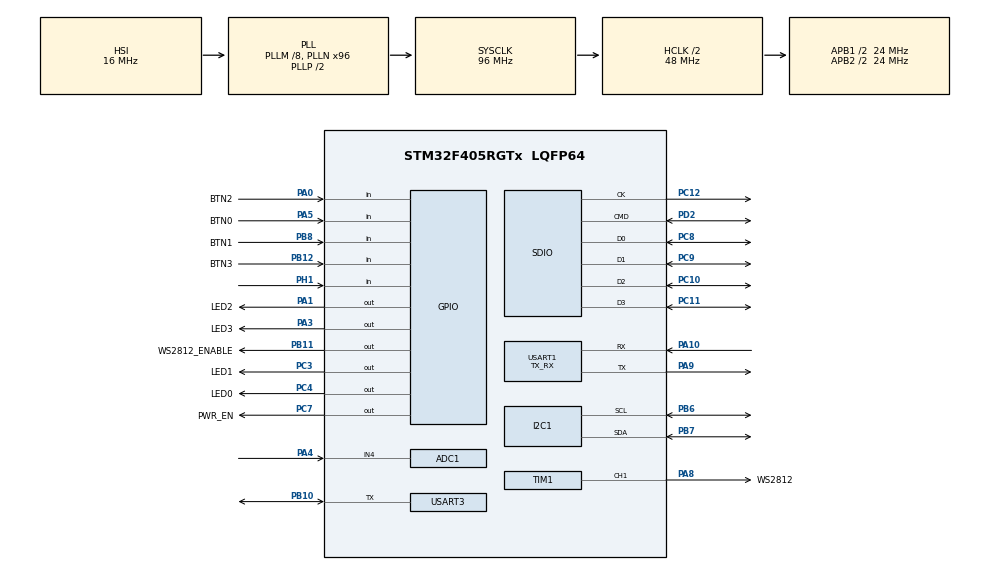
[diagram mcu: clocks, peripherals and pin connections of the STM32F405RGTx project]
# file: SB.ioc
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ADC1.Channel-0\#ChannelRegularConversion=ADC_CHANNEL_4
ADC1.Channel-3\#ChannelRegularConversion=ADC_CHANNEL_TEMPSENSOR
ADC1.DMAContinuousRequests=ENABLE
ADC1.EOCSelection=ADC_EOC_SEQ_CONV
ADC1.ExternalTrigConv=ADC_EXTERNALTRIGCONV_T3_TRGO
ADC1.InjNumberOfConversion=0
ADC1.NbrOfConversion=2
ADC1.NbrOfConversionFlag=1
ADC1.Rank-0\#ChannelRegularConversion=1
ADC1.Rank-3\#ChannelRegularConversion=2
ADC1.SamplingTime-0\#ChannelRegularConversion=ADC_SAMPLETIME_56CYCLES
ADC1.SamplingTime-3\#ChannelRegularConversion=ADC_SAMPLETIME_56CYCLES
ADC1.master=1
Dma.ADC1.0.Direction=DMA_PERIPH_TO_MEMORY
Dma.ADC1.0.FIFOMode=DMA_FIFOMODE_DISABLE
Dma.ADC1.0.Instance=DMA2_Stream0
Dma.ADC1.0.MemDataAlignment=DMA_MDATAALIGN_HALFWORD
Dma.ADC1.0.MemInc=DMA_MINC_ENABLE
Dma.ADC1.0.Mode=DMA_CIRCULAR
Dma.ADC1.0.PeriphDataAlignment=DMA_PDATAALIGN_HALFWORD
Dma.ADC1.0.PeriphInc=DMA_PINC_DISABLE
Dma.ADC1.0.Priority=DMA_PRIORITY_LOW
Dma.Request0=ADC1
Dma.Request1=TIM1_CH1
Dma.Request2=SDIO_RX
Dma.Request3=SDIO_TX
Dma.SDIO_RX.2.Direction=DMA_PERIPH_TO_MEMORY
Dma.SDIO_RX.2.FIFOMode=DMA_FIFOMODE_ENABLE
Dma.SDIO_RX.2.FIFOThreshold=DMA_FIFO_THRESHOLD_FULL
Dma.SDIO_RX.2.Instance=DMA2_Stream3
Dma.SDIO_RX.2.MemBurst=DMA_MBURST_INC4
Dma.SDIO_RX.2.MemDataAlignment=DMA_MDATAALIGN_WORD
Dma.SDIO_RX.2.MemInc=DMA_MINC_ENABLE
Dma.SDIO_RX.2.Mode=DMA_PFCTRL
Dma.SDIO_RX.2.PeriphBurst=DMA_PBURST_INC4
Dma.SDIO_RX.2.PeriphDataAlignment=DMA_PDATAALIGN_WORD
Dma.SDIO_RX.2.PeriphInc=DMA_PINC_DISABLE
Dma.SDIO_RX.2.Priority=DMA_PRIORITY_LOW
Dma.SDIO_TX.3.Direction=DMA_MEMORY_TO_PERIPH
Dma.SDIO_TX.3.FIFOMode=DMA_FIFOMODE_ENABLE
Dma.SDIO_TX.3.FIFOThreshold=DMA_FIFO_THRESHOLD_FULL
Dma.SDIO_TX.3.Instance=DMA2_Stream6
Dma.SDIO_TX.3.MemBurst=DMA_MBURST_INC4
Dma.SDIO_TX.3.MemDataAlignment=DMA_MDATAALIGN_WORD
Dma.SDIO_TX.3.MemInc=DMA_MINC_ENABLE
Dma.SDIO_TX.3.Mode=DMA_PFCTRL
Dma.SDIO_TX.3.PeriphBurst=DMA_PBURST_INC4
Dma.SDIO_TX.3.PeriphDataAlignment=DMA_PDATAALIGN_WORD
Dma.SDIO_TX.3.PeriphInc=DMA_PINC_DISABLE
Dma.SDIO_TX.3.Priority=DMA_PRIORITY_LOW
Dma.TIM1_CH1.1.Direction=DMA_MEMORY_TO_PERIPH
Dma.TIM1_CH1.1.FIFOMode=DMA_FIFOMODE_DISABLE
Dma.TIM1_CH1.1.Instance=DMA2_Stream1
Dma.TIM1_CH1.1.MemDataAlignment=DMA_MDATAALIGN_HALFWORD
Dma.TIM1_CH1.1.MemInc=DMA_MINC_ENABLE
Dma.TIM1_CH1.1.Mode=DMA_NORMAL
Dma.TIM1_CH1.1.PeriphDataAlignment=DMA_PDATAALIGN_HALFWORD
Dma.TIM1_CH1.1.PeriphInc=DMA_PINC_DISABLE
Dma.TIM1_CH1.1.Priority=DMA_PRIORITY_LOW
FATFS.BSP.number=1
FATFS.USE_DMA_CODE_SD=1
FATFS._MAX_SS=4096
FATFS._USE_LFN=1
FATFS0.BSP.STBoard=false
FATFS0.BSP.api=Unknown
FATFS0.BSP.instance=PH1-OSC_OUT
FATFS0.BSP.ip=GPIO
FATFS0.BSP.mode=Input
FATFS0.BSP.name=Detect_SDIO
FATFS0.BSP.solution=PH1-OSC_OUT
IWDG.Prescaler=IWDG_PRESCALER_32
IWDG.Reload=1000
Mcu.Family=STM32F4
Mcu.Name=STM32F405RGTx
Mcu.Package=LQFP64
NVIC.DMA2_Stream0_IRQn=true\:0\:0\:false\:false\:true\:false\:true\:true
NVIC.DMA2_Stream1_IRQn=true\:0\:0\:false\:false\:true\:false\:true\:true
NVIC.DMA2_Stream3_IRQn=true\:0\:0\:false\:false\:true\:false\:true\:true
NVIC.DMA2_Stream6_IRQn=true\:0\:0\:false\:false\:true\:false\:true\:true
NVIC.PriorityGroup=NVIC_PRIORITYGROUP_4
NVIC.SDIO_IRQn=true\:0\:0\:false\:false\:true\:true\:true\:true
NVIC.USART1_IRQn=true\:0\:0\:false\:false\:true\:true\:true\:true
PA0-WKUP.GPIO_Label=BTN2
PA0-WKUP.GPIO_PuPd=GPIO_PULLUP
PA0-WKUP.Signal=GPIO_Input
PA1.GPIO_Label=LED2
PA1.Signal=GPIO_Output
PA10.Mode=Asynchronous
PA10.Signal=USART1_RX
PA13.Signal=SYS_JTMS-SWDIO
PA14.Signal=SYS_JTCK-SWCLK
PA3.GPIO_Label=LED3
PA3.Signal=GPIO_Output
PA4.Signal=ADCx_IN4
PA5.GPIO_Label=BTN0
PA5.Signal=GPIO_Input
PA8.GPIO_Label=WS2812
PA8.Signal=S_TIM1_CH1
PA9.Mode=Asynchronous
PA9.Signal=USART1_TX
PB10.Mode=Half_duplex(single_wire_mode)
PB10.Signal=USART3_TX
PB11.GPIO_Label=WS2812_ENABLE
PB11.Signal=GPIO_Output
PB12.GPIO_Label=BTN3
PB12.GPIO_PuPd=GPIO_PULLUP
PB12.Signal=GPIO_Input
PB6.GPIO_Pu=GPIO_PULLUP
PB6.Mode=I2C
PB6.Signal=I2C1_SCL
PB7.GPIO_Pu=GPIO_PULLUP
PB7.Mode=I2C
PB7.Signal=I2C1_SDA
PB8.GPIO_Label=BTN1
PB8.GPIO_PuPd=GPIO_PULLUP
PB8.Signal=GPIO_Input
PC10.Mode=SD_4_bits_Wide_bus
PC10.Signal=SDIO_D2
PC11.Mode=SD_4_bits_Wide_bus
PC11.Signal=SDIO_D3
PC12.Mode=SD_4_bits_Wide_bus
PC12.Signal=SDIO_CK
PC14-OSC32_IN.Mode=LSE-External-Oscillator
PC14-OSC32_IN.Signal=RCC_OSC32_IN
PC15-OSC32_OUT.Mode=LSE-External-Oscillator
PC15-OSC32_OUT.Signal=RCC_OSC32_OUT
PC3.GPIO_Label=LED1
PC3.Signal=GPIO_Output
PC4.GPIO_Label=LED0
PC4.Signal=GPIO_Output
PC7.GPIO_Label=PWR_EN
PC7.Signal=GPIO_Output
PC8.Mode=SD_4_bits_Wide_bus
PC8.Signal=SDIO_D0
PC9.Mode=SD_4_bits_Wide_bus
PC9.Signal=SDIO_D1
PD2.Mode=SD_4_bits_Wide_bus
PD2.Signal=SDIO_CMD
PH1-OSC_OUT.Signal=GPIO_Input
ProjectManager.HeapSize=0x400
ProjectManager.StackSize=0x400
ProjectManager.TargetToolchain=Makefile
RCC.48MHZClocksFreq_Value=48000000
RCC.AHBCLKDivider=RCC_SYSCLK_DIV2
RCC.AHBFreq_Value=48000000
RCC.APB1CLKDivider=RCC_HCLK_DIV2
RCC.APB1Freq_Value=24000000
RCC.APB1TimFreq_Value=48000000
RCC.APB2CLKDivider=RCC_HCLK_DIV2
RCC.APB2Freq_Value=24000000
RCC.APB2TimFreq_Value=48000000
RCC.CortexFreq_Value=48000000
RCC.HCLKFreq_Value=48000000
RCC.HSE_VALUE=25000000
RCC.HSI_VALUE=16000000
RCC.PLLM=8
RCC.PLLN=96
RCC.SYSCLKFreq_VALUE=96000000
RCC.SYSCLKSource=RCC_SYSCLKSOURCE_PLLCLK
RCC.VCOOutputFreq_Value=192000000
RTC.Format=RTC_FORMAT_BIN
RTC.WeekDay=RTC_WEEKDAY_FRIDAY
RTC.Year=20
SDIO.ClockDiv=250
SH.ADCx_IN4.0=ADC1_IN4,IN4
SH.S_TIM1_CH1.0=TIM1_CH1,PWM Generation1 CH1
TIM1.AutoReloadPreload=TIM_AUTORELOAD_PRELOAD_ENABLE
TIM1.Channel-PWM\ Generation1\ CH1=TIM_CHANNEL_1
TIM1.OCFastMode_PWM-PWM\ Generation1\ CH1=TIM_OCFAST_ENABLE
TIM1.OCIdleState_1=TIM_OCIDLESTATE_SET
TIM1.OCPolarity_1=TIM_OCPOLARITY_LOW
TIM1.Period=29
TIM1.Prescaler=1
TIM3.AutoReloadPreload=TIM_AUTORELOAD_PRELOAD_ENABLE
TIM3.Period=999
TIM3.Prescaler=11
TIM3.TIM_MasterOutputTrigger=TIM_TRGO_UPDATE
USART1.Mode=MODE_TX_RX
USART1.VirtualMode=VM_ASYNC
USART3.VirtualMode=VM_ASYNC
VP_ADC1_TempSens_Input.Mode=IN-TempSens
VP_CRC_VS_CRC.Mode=CRC_Activate
VP_FATFS_VS_SDIO.Mode=SDIO
VP_IWDG_VS_IWDG.Mode=IWDG_Activate
VP_RNG_VS_RNG.Mode=RNG_Activate
VP_RTC_VS_RTC_Activate.Mode=RTC_Enabled
VP_RTC_VS_RTC_Calendar.Mode=RTC_Calendar
VP_TIM1_VS_ClockSourceINT.Mode=Internal
VP_TIM3_VS_ClockSourceINT.Mode=Internal
board=custom

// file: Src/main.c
/* USER CODE BEGIN Header */
/**
  ******************************************************************************
  * @file           : main.c
  * @brief          : Main program body
  ******************************************************************************
  * @attention
  *
  * <h2><center>&copy; Copyright (c) 2019 STMicroelectronics.
  * All rights reserved.</center></h2>
  *
  * This software component is licensed by ST under BSD 3-Clause license,
  * the "License"; You may not use this file except in compliance with the
  * License. You may obtain a copy of the License at:
  *                        opensource.org/licenses/BSD-3-Clause
  *
  ******************************************************************************
  */
/* USER CODE END Header */
#include "main.h"
#include "fatfs.h"

/* USER CODE BEGIN PD */
void init(void);
void loop(void);
/* USER CODE END PD */

ADC_HandleTypeDef hadc1;
DMA_HandleTypeDef hdma_adc1;

CRC_HandleTypeDef hcrc;

I2C_HandleTypeDef hi2c1;

IWDG_HandleTypeDef hiwdg;

RNG_HandleTypeDef hrng;

RTC_HandleTypeDef hrtc;

SD_HandleTypeDef hsd;
DMA_HandleTypeDef hdma_sdio_rx;
DMA_HandleTypeDef hdma_sdio_tx;

TIM_HandleTypeDef htim1;
TIM_HandleTypeDef htim3;
DMA_HandleTypeDef hdma_tim1_ch1;

UART_HandleTypeDef huart1;
UART_HandleTypeDef huart3;

void SystemClock_Config(void);
static void MX_GPIO_Init(void);
static void MX_DMA_Init(void);
static void MX_ADC1_Init(void);
static void MX_I2C1_Init(void);
static void MX_SDIO_SD_Init(void);
static void MX_TIM1_Init(void);
static void MX_TIM3_Init(void);
static void MX_USART1_UART_Init(void);
static void MX_CRC_Init(void);
static void MX_RNG_Init(void);
static void MX_IWDG_Init(void);
static void MX_USART3_UART_Init(void);
static void MX_RTC_Init(void);

int main(void)
{

  /* MCU Configuration--------------------------------------------------------*/

  /* Reset of all peripherals, Initializes the Flash interface and the Systick. */
  HAL_Init();

  /* Configure the system clock */
  SystemClock_Config();

  /* Initialize all configured peripherals */
  MX_GPIO_Init();
  MX_DMA_Init();
  MX_ADC1_Init();
  MX_I2C1_Init();
  MX_SDIO_SD_Init();
  MX_TIM1_Init();
  MX_TIM3_Init();
  MX_USART1_UART_Init();
  MX_CRC_Init();
  MX_RNG_Init();
  MX_FATFS_Init();
  MX_IWDG_Init();
  MX_USART3_UART_Init();
  MX_RTC_Init();
  /* USER CODE BEGIN 2 */
init();
  /* USER CODE END 2 */

  /* Infinite loop */
  /* USER CODE BEGIN WHILE */
  while (1)
  {
      loop();
    /* USER CODE END WHILE */

  }
}

void SystemClock_Config(void)
{
  RCC_OscInitTypeDef RCC_OscInitStruct = {0};
  RCC_ClkInitTypeDef RCC_ClkInitStruct = {0};
  RCC_PeriphCLKInitTypeDef PeriphClkInitStruct = {0};

  /** Configure the main internal regulator output voltage
  */
  __HAL_RCC_PWR_CLK_ENABLE();
  __HAL_PWR_VOLTAGESCALING_CONFIG(PWR_REGULATOR_VOLTAGE_SCALE1);
  /** Initializes the RCC Oscillators according to the specified parameters
  * in the RCC_OscInitTypeDef structure.
  */
  RCC_OscInitStruct.OscillatorType = RCC_OSCILLATORTYPE_HSI|RCC_OSCILLATORTYPE_LSI;
  RCC_OscInitStruct.HSIState = RCC_HSI_ON;
  RCC_OscInitStruct.HSICalibrationValue = RCC_HSICALIBRATION_DEFAULT;
  RCC_OscInitStruct.LSIState = RCC_LSI_ON;
  RCC_OscInitStruct.PLL.PLLState = RCC_PLL_ON;
  RCC_OscInitStruct.PLL.PLLSource = RCC_PLLSOURCE_HSI;
  RCC_OscInitStruct.PLL.PLLM = 8;
  RCC_OscInitStruct.PLL.PLLN = 96;
  RCC_OscInitStruct.PLL.PLLP = RCC_PLLP_DIV2;
  RCC_OscInitStruct.PLL.PLLQ = 4;
  if (HAL_RCC_OscConfig(&RCC_OscInitStruct) != HAL_OK)
  {
    Error_Handler();
  }
  /** Initializes the CPU, AHB and APB buses clocks
  */
  RCC_ClkInitStruct.ClockType = RCC_CLOCKTYPE_HCLK|RCC_CLOCKTYPE_SYSCLK
                              |RCC_CLOCKTYPE_PCLK1|RCC_CLOCKTYPE_PCLK2;
  RCC_ClkInitStruct.SYSCLKSource = RCC_SYSCLKSOURCE_PLLCLK;
  RCC_ClkInitStruct.AHBCLKDivider = RCC_SYSCLK_DIV2;
  RCC_ClkInitStruct.APB1CLKDivider = RCC_HCLK_DIV2;
  RCC_ClkInitStruct.APB2CLKDivider = RCC_HCLK_DIV2;

  if (HAL_RCC_ClockConfig(&RCC_ClkInitStruct, FLASH_LATENCY_1) != HAL_OK)
  {
    Error_Handler();
  }
  PeriphClkInitStruct.PeriphClockSelection = RCC_PERIPHCLK_RTC;
  PeriphClkInitStruct.RTCClockSelection = RCC_RTCCLKSOURCE_LSI;
  if (HAL_RCCEx_PeriphCLKConfig(&PeriphClkInitStruct) != HAL_OK)
  {
    Error_Handler();
  }
}

static void MX_ADC1_Init(void)
{

  ADC_ChannelConfTypeDef sConfig = {0};

  /** Configure the global features of the ADC (Clock, Resolution, Data Alignment and number of conversion)
  */
  hadc1.Instance = ADC1;
  hadc1.Init.ClockPrescaler = ADC_CLOCK_SYNC_PCLK_DIV2;
  hadc1.Init.Resolution = ADC_RESOLUTION_12B;
  hadc1.Init.ScanConvMode = ENABLE;
  hadc1.Init.ContinuousConvMode = DISABLE;
  hadc1.Init.DiscontinuousConvMode = DISABLE;
  hadc1.Init.ExternalTrigConvEdge = ADC_EXTERNALTRIGCONVEDGE_RISING;
  hadc1.Init.ExternalTrigConv = ADC_EXTERNALTRIGCONV_T3_TRGO;
  hadc1.Init.DataAlign = ADC_DATAALIGN_RIGHT;
  hadc1.Init.NbrOfConversion = 2;
  hadc1.Init.DMAContinuousRequests = ENABLE;
  hadc1.Init.EOCSelection = ADC_EOC_SEQ_CONV;
  if (HAL_ADC_Init(&hadc1) != HAL_OK)
  {
    Error_Handler();
  }
  /** Configure for the selected ADC regular channel its corresponding rank in the sequencer and its sample time.
  */
  sConfig.Channel = ADC_CHANNEL_4;
  sConfig.Rank = 1;
  sConfig.SamplingTime = ADC_SAMPLETIME_56CYCLES;
  if (HAL_ADC_ConfigChannel(&hadc1, &sConfig) != HAL_OK)
  {
    Error_Handler();
  }
  /** Configure for the selected ADC regular channel its corresponding rank in the sequencer and its sample time.
  */
  sConfig.Channel = ADC_CHANNEL_TEMPSENSOR;
  sConfig.Rank = 2;
  if (HAL_ADC_ConfigChannel(&hadc1, &sConfig) != HAL_OK)
  {
    Error_Handler();
  }

}

static void MX_CRC_Init(void)
{

  hcrc.Instance = CRC;
  if (HAL_CRC_Init(&hcrc) != HAL_OK)
  {
    Error_Handler();
  }

}

static void MX_I2C1_Init(void)
{

  hi2c1.Instance = I2C1;
  hi2c1.Init.ClockSpeed = 100000;
  hi2c1.Init.DutyCycle = I2C_DUTYCYCLE_2;
  hi2c1.Init.OwnAddress1 = 0;
  hi2c1.Init.AddressingMode = I2C_ADDRESSINGMODE_7BIT;
  hi2c1.Init.DualAddressMode = I2C_DUALADDRESS_DISABLE;
  hi2c1.Init.OwnAddress2 = 0;
  hi2c1.Init.GeneralCallMode = I2C_GENERALCALL_DISABLE;
  hi2c1.Init.NoStretchMode = I2C_NOSTRETCH_DISABLE;
  if (HAL_I2C_Init(&hi2c1) != HAL_OK)
  {
    Error_Handler();
  }

}

static void MX_IWDG_Init(void)
{

  hiwdg.Instance = IWDG;
  hiwdg.Init.Prescaler = IWDG_PRESCALER_32;
  hiwdg.Init.Reload = 1000;
  if (HAL_IWDG_Init(&hiwdg) != HAL_OK)
  {
    Error_Handler();
  }

}

static void MX_RNG_Init(void)
{

  hrng.Instance = RNG;
  if (HAL_RNG_Init(&hrng) != HAL_OK)
  {
    Error_Handler();
  }

}

static void MX_RTC_Init(void)
{

  RTC_TimeTypeDef sTime = {0};
  RTC_DateTypeDef sDate = {0};

  /** Initialize RTC Only
  */
  hrtc.Instance = RTC;
  hrtc.Init.HourFormat = RTC_HOURFORMAT_24;
  hrtc.Init.AsynchPrediv = 127;
  hrtc.Init.SynchPrediv = 255;
  hrtc.Init.OutPut = RTC_OUTPUT_DISABLE;
  hrtc.Init.OutPutPolarity = RTC_OUTPUT_POLARITY_HIGH;
  hrtc.Init.OutPutType = RTC_OUTPUT_TYPE_OPENDRAIN;
  if (HAL_RTC_Init(&hrtc) != HAL_OK)
  {
    Error_Handler();
  }

  /** Initialize RTC and set the Time and Date
  */
  sTime.Hours = 0;
  sTime.Minutes = 0;
  sTime.Seconds = 0;
  sTime.DayLightSaving = RTC_DAYLIGHTSAVING_NONE;
  sTime.StoreOperation = RTC_STOREOPERATION_RESET;
  // if (HAL_RTC_SetTime(&hrtc, &sTime, RTC_FORMAT_BIN) != HAL_OK)
  {
    Error_Handler();
  }
  sDate.WeekDay = RTC_WEEKDAY_FRIDAY;
  sDate.Month = RTC_MONTH_JANUARY;
  sDate.Date = 1;
  sDate.Year = 20;

  // if (HAL_RTC_SetDate(&hrtc, &sDate, RTC_FORMAT_BIN) != HAL_OK)
  {
    Error_Handler();
  }

}

static void MX_SDIO_SD_Init(void)
{

  hsd.Instance = SDIO;
  hsd.Init.ClockEdge = SDIO_CLOCK_EDGE_RISING;
  hsd.Init.ClockBypass = SDIO_CLOCK_BYPASS_DISABLE;
  hsd.Init.ClockPowerSave = SDIO_CLOCK_POWER_SAVE_DISABLE;
  hsd.Init.BusWide = SDIO_BUS_WIDE_1B;
  hsd.Init.HardwareFlowControl = SDIO_HARDWARE_FLOW_CONTROL_DISABLE;
  hsd.Init.ClockDiv = 250;

}

static void MX_TIM1_Init(void)
{

  TIM_ClockConfigTypeDef sClockSourceConfig = {0};
  TIM_MasterConfigTypeDef sMasterConfig = {0};
  TIM_OC_InitTypeDef sConfigOC = {0};
  TIM_BreakDeadTimeConfigTypeDef sBreakDeadTimeConfig = {0};

  htim1.Instance = TIM1;
  htim1.Init.Prescaler = 1;
  htim1.Init.CounterMode = TIM_COUNTERMODE_UP;
  htim1.Init.Period = 29;
  htim1.Init.ClockDivision = TIM_CLOCKDIVISION_DIV1;
  htim1.Init.RepetitionCounter = 0;
  htim1.Init.AutoReloadPreload = TIM_AUTORELOAD_PRELOAD_ENABLE;
  if (HAL_TIM_Base_Init(&htim1) != HAL_OK)
  {
    Error_Handler();
  }
  sClockSourceConfig.ClockSource = TIM_CLOCKSOURCE_INTERNAL;
  if (HAL_TIM_ConfigClockSource(&htim1, &sClockSourceConfig) != HAL_OK)
  {
    Error_Handler();
  }
  if (HAL_TIM_PWM_Init(&htim1) != HAL_OK)
  {
    Error_Handler();
  }
  sMasterConfig.MasterOutputTrigger = TIM_TRGO_RESET;
  sMasterConfig.MasterSlaveMode = TIM_MASTERSLAVEMODE_DISABLE;
  if (HAL_TIMEx_MasterConfigSynchronization(&htim1, &sMasterConfig) != HAL_OK)
  {
    Error_Handler();
  }
  sConfigOC.OCMode = TIM_OCMODE_PWM1;
  sConfigOC.Pulse = 0;
  sConfigOC.OCPolarity = TIM_OCPOLARITY_LOW;
  sConfigOC.OCNPolarity = TIM_OCNPOLARITY_HIGH;
  sConfigOC.OCFastMode = TIM_OCFAST_ENABLE;
  sConfigOC.OCIdleState = TIM_OCIDLESTATE_SET;
  sConfigOC.OCNIdleState = TIM_OCNIDLESTATE_RESET;
  if (HAL_TIM_PWM_ConfigChannel(&htim1, &sConfigOC, TIM_CHANNEL_1) != HAL_OK)
  {
    Error_Handler();
  }
  sBreakDeadTimeConfig.OffStateRunMode = TIM_OSSR_DISABLE;
  sBreakDeadTimeConfig.OffStateIDLEMode = TIM_OSSI_DISABLE;
  sBreakDeadTimeConfig.LockLevel = TIM_LOCKLEVEL_OFF;
  sBreakDeadTimeConfig.DeadTime = 0;
  sBreakDeadTimeConfig.BreakState = TIM_BREAK_DISABLE;
  sBreakDeadTimeConfig.BreakPolarity = TIM_BREAKPOLARITY_HIGH;
  sBreakDeadTimeConfig.AutomaticOutput = TIM_AUTOMATICOUTPUT_DISABLE;
  if (HAL_TIMEx_ConfigBreakDeadTime(&htim1, &sBreakDeadTimeConfig) != HAL_OK)
  {
    Error_Handler();
  }
  HAL_TIM_MspPostInit(&htim1);

}

static void MX_TIM3_Init(void)
{

  TIM_ClockConfigTypeDef sClockSourceConfig = {0};
  TIM_MasterConfigTypeDef sMasterConfig = {0};

  htim3.Instance = TIM3;
  htim3.Init.Prescaler = 11;
  htim3.Init.CounterMode = TIM_COUNTERMODE_UP;
  htim3.Init.Period = 999;
  htim3.Init.ClockDivision = TIM_CLOCKDIVISION_DIV1;
  htim3.Init.AutoReloadPreload = TIM_AUTORELOAD_PRELOAD_ENABLE;
  if (HAL_TIM_Base_Init(&htim3) != HAL_OK)
  {
    Error_Handler();
  }
  sClockSourceConfig.ClockSource = TIM_CLOCKSOURCE_INTERNAL;
  if (HAL_TIM_ConfigClockSource(&htim3, &sClockSourceConfig) != HAL_OK)
  {
    Error_Handler();
  }
  sMasterConfig.MasterOutputTrigger = TIM_TRGO_UPDATE;
  sMasterConfig.MasterSlaveMode = TIM_MASTERSLAVEMODE_DISABLE;
  if (HAL_TIMEx_MasterConfigSynchronization(&htim3, &sMasterConfig) != HAL_OK)
  {
    Error_Handler();
  }

}

static void MX_USART1_UART_Init(void)
{

  huart1.Instance = USART1;
  huart1.Init.BaudRate = 9600;
  huart1.Init.WordLength = UART_WORDLENGTH_8B;
  huart1.Init.StopBits = UART_STOPBITS_1;
  huart1.Init.Parity = UART_PARITY_NONE;
  huart1.Init.Mode = UART_MODE_TX_RX;
  huart1.Init.HwFlowCtl = UART_HWCONTROL_NONE;
  huart1.Init.OverSampling = UART_OVERSAMPLING_16;
  if (HAL_UART_Init(&huart1) != HAL_OK)
  {
    Error_Handler();
  }

}

static void MX_USART3_UART_Init(void)
{

  huart3.Instance = USART3;
  huart3.Init.BaudRate = 115200;
  huart3.Init.WordLength = UART_WORDLENGTH_8B;
  huart3.Init.StopBits = UART_STOPBITS_1;
  huart3.Init.Parity = UART_PARITY_NONE;
  huart3.Init.Mode = UART_MODE_TX_RX;
  huart3.Init.HwFlowCtl = UART_HWCONTROL_NONE;
  huart3.Init.OverSampling = UART_OVERSAMPLING_16;
  if (HAL_HalfDuplex_Init(&huart3) != HAL_OK)
  {
    Error_Handler();
  }

}

static void MX_DMA_Init(void)
{

  /* DMA controller clock enable */
  __HAL_RCC_DMA2_CLK_ENABLE();

  /* DMA interrupt init */
  /* DMA2_Stream0_IRQn interrupt configuration */
  HAL_NVIC_SetPriority(DMA2_Stream0_IRQn, 0, 0);
  HAL_NVIC_EnableIRQ(DMA2_Stream0_IRQn);
  /* DMA2_Stream1_IRQn interrupt configuration */
  HAL_NVIC_SetPriority(DMA2_Stream1_IRQn, 0, 0);
  HAL_NVIC_EnableIRQ(DMA2_Stream1_IRQn);
  /* DMA2_Stream3_IRQn interrupt configuration */
  HAL_NVIC_SetPriority(DMA2_Stream3_IRQn, 0, 0);
  HAL_NVIC_EnableIRQ(DMA2_Stream3_IRQn);
  /* DMA2_Stream6_IRQn interrupt configuration */
  HAL_NVIC_SetPriority(DMA2_Stream6_IRQn, 0, 0);
  HAL_NVIC_EnableIRQ(DMA2_Stream6_IRQn);

}

static void MX_GPIO_Init(void)
{
  GPIO_InitTypeDef GPIO_InitStruct = {0};

  /* GPIO Ports Clock Enable */
  __HAL_RCC_GPIOC_CLK_ENABLE();
  __HAL_RCC_GPIOH_CLK_ENABLE();
  __HAL_RCC_GPIOA_CLK_ENABLE();
  __HAL_RCC_GPIOB_CLK_ENABLE();
  __HAL_RCC_GPIOD_CLK_ENABLE();

  /*Configure GPIO pin Output Level */
  HAL_GPIO_WritePin(GPIOC, LED1_Pin|LED0_Pin|PWR_EN_Pin, GPIO_PIN_RESET);

  /*Configure GPIO pin Output Level */
  HAL_GPIO_WritePin(GPIOA, LED2_Pin|LED3_Pin, GPIO_PIN_RESET);

  /*Configure GPIO pin Output Level */
  HAL_GPIO_WritePin(WS2812_ENABLE_GPIO_Port, WS2812_ENABLE_Pin, GPIO_PIN_RESET);

  /*Configure GPIO pin : PH1 */
  GPIO_InitStruct.Pin = GPIO_PIN_1;
  GPIO_InitStruct.Mode = GPIO_MODE_INPUT;
  GPIO_InitStruct.Pull = GPIO_NOPULL;
  HAL_GPIO_Init(GPIOH, &GPIO_InitStruct);

  /*Configure GPIO pins : LED1_Pin LED0_Pin PWR_EN_Pin */
  GPIO_InitStruct.Pin = LED1_Pin|LED0_Pin|PWR_EN_Pin;
  GPIO_InitStruct.Mode = GPIO_MODE_OUTPUT_PP;
  GPIO_InitStruct.Pull = GPIO_NOPULL;
  GPIO_InitStruct.Speed = GPIO_SPEED_FREQ_LOW;
  HAL_GPIO_Init(GPIOC, &GPIO_InitStruct);

  /*Configure GPIO pin : BTN2_Pin */
  GPIO_InitStruct.Pin = BTN2_Pin;
  GPIO_InitStruct.Mode = GPIO_MODE_INPUT;
  GPIO_InitStruct.Pull = GPIO_PULLUP;
  HAL_GPIO_Init(BTN2_GPIO_Port, &GPIO_InitStruct);

  /*Configure GPIO pins : LED2_Pin LED3_Pin */
  GPIO_InitStruct.Pin = LED2_Pin|LED3_Pin;
  GPIO_InitStruct.Mode = GPIO_MODE_OUTPUT_PP;
  GPIO_InitStruct.Pull = GPIO_NOPULL;
  GPIO_InitStruct.Speed = GPIO_SPEED_FREQ_LOW;
  HAL_GPIO_Init(GPIOA, &GPIO_InitStruct);

  /*Configure GPIO pin : BTN0_Pin */
  GPIO_InitStruct.Pin = BTN0_Pin;
  GPIO_InitStruct.Mode = GPIO_MODE_INPUT;
  GPIO_InitStruct.Pull = GPIO_NOPULL;
  HAL_GPIO_Init(BTN0_GPIO_Port, &GPIO_InitStruct);

  /*Configure GPIO pin : WS2812_ENABLE_Pin */
  GPIO_InitStruct.Pin = WS2812_ENABLE_Pin;
  GPIO_InitStruct.Mode = GPIO_MODE_OUTPUT_PP;
  GPIO_InitStruct.Pull = GPIO_NOPULL;
  GPIO_InitStruct.Speed = GPIO_SPEED_FREQ_LOW;
  HAL_GPIO_Init(WS2812_ENABLE_GPIO_Port, &GPIO_InitStruct);

  /*Configure GPIO pins : BTN3_Pin BTN1_Pin */
  GPIO_InitStruct.Pin = BTN3_Pin|BTN1_Pin;
  GPIO_InitStruct.Mode = GPIO_MODE_INPUT;
  GPIO_InitStruct.Pull = GPIO_PULLUP;
  HAL_GPIO_Init(GPIOB, &GPIO_InitStruct);

}

void Error_Handler(void)
{
}

/************************ (C) COPYRIGHT STMicroelectronics *****END OF FILE****/
